AUTOSAR XML (schema 4-3-0)
package /ComponentTypes
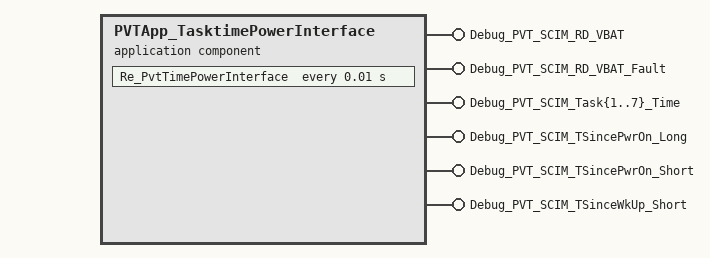
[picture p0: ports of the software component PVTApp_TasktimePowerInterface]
  application sw component type PVTApp_TasktimePowerInterface
    12 x provide port:
      Debug_PVT_SCIM_RD_VBAT: nonqueued-sender-com-spec{data-element=Debug_PVT_SCIM_RD_VBAT, init-value=0}, provided-interface=Debug_PVT_SCIM_RD_VBAT
      Debug_PVT_SCIM_RD_VBAT_Fault: nonqueued-sender-com-spec{data-element=Debug_PVT_SCIM_RD_VBAT_Fault, init-value=0}, provided-interface=Debug_PVT_SCIM_RD_VBAT_Fault
      Debug_PVT_SCIM_Task{1..7}_Time: nonqueued-sender-com-spec{data-element=Debug_PVT_SCIM_Task{1..7}_Time, init-value=0}, provided-interface=Debug_PVT_SCIM_Task{1..7}_Time
      Debug_PVT_SCIM_TSincePwrOn_Long: nonqueued-sender-com-spec{data-element=Debug_PVT_SCIM_TSincePwrOn_Long, init-value=0}, provided-interface=Debug_PVT_SCIM_TSincePwrOn_Long
      Debug_PVT_SCIM_TSincePwrOn_Short: nonqueued-sender-com-spec{data-element=Debug_PVT_SCIM_TSincePwrOn_Short, init-value=0}, provided-interface=Debug_PVT_SCIM_TSincePwrOn_Short
      Debug_PVT_SCIM_TSinceWkUp_Short: nonqueued-sender-com-spec{data-element=Debug_PVT_SCIM_TSinceWkUp_Short, init-value=0}, provided-interface=Debug_PVT_SCIM_TSinceWkUp_Short
    behavior PVTApp_TasktimePowerInterface_InternalBehavior
      timing event TMT_Re_PvtTimePowerInterface: start-on-event=Re_PvtTimePowerInterface, period=0.01
      runnable Re_PvtTimePowerInterface
        data-send-points:
          12 x access:
            SEND_Debug_PVT_SCIM_RD_VBAT_Debug_PVT_SCIM_RD_VBAT: accessed-variable=Debug_PVT_SCIM_RD_VBAT.Debug_PVT_SCIM_RD_VBAT
            SEND_Debug_PVT_SCIM_RD_VBAT_Fault_Debug_PVT_SCIM_RD_VBAT_Fault: accessed-variable=Debug_PVT_SCIM_RD_VBAT_Fault.Debug_PVT_SCIM_RD_VBAT_Fault
            SEND_Debug_PVT_SCIM_Task{1..7}_Time_Debug_PVT_SCIM_Task{1..7}_Time: accessed-variable=Debug_PVT_SCIM_Task{1..7}_Time.Debug_PVT_SCIM_Task{1..7}_Time
            SEND_Debug_PVT_SCIM_TSincePwrOn_Long_Debug_PVT_SCIM_TSincePwrOn_Long: accessed-variable=Debug_PVT_SCIM_TSincePwrOn_Long.Debug_PVT_SCIM_TSincePwrOn_Long
            SEND_Debug_PVT_SCIM_TSincePwrOn_Short_Debug_PVT_SCIM_TSincePwrOn_Short: accessed-variable=Debug_PVT_SCIM_TSincePwrOn_Short.Debug_PVT_SCIM_TSincePwrOn_Short
            SEND_Debug_PVT_SCIM_TSinceWkUp_Short_Debug_PVT_SCIM_TSinceWkUp_Short: accessed-variable=Debug_PVT_SCIM_TSinceWkUp_Short.Debug_PVT_SCIM_TSinceWkUp_Short
  swc implementation PVTApp_TasktimePowerInterface_Implementation: behavior=PVTApp_TasktimePowerInterface_InternalBehavior
    code-descriptors:
      code Default: artifact-descriptors=autosar-engineering-object=category=SWSRC
